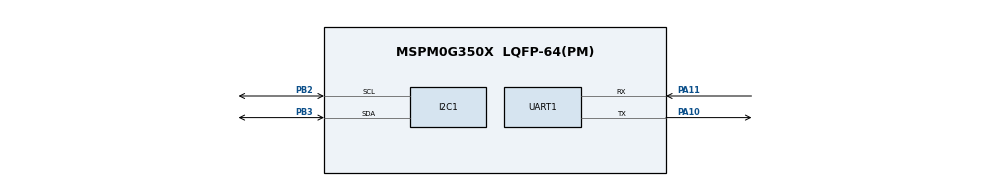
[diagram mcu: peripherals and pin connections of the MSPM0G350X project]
/**
 * @cliArgs --device "MSPM0G350X" --package "LQFP-64(PM)" --part "Default" --product "mspm0_sdk@2.01.00.03"
 * @versions {"tool":"1.20.0+3587"}
 */

/**
 * Import the modules used in this configuration.
 */
const I2C    = scripting.addModule("/ti/driverlib/I2C", {}, false);
const I2C1   = I2C.addInstance();
const SYSCTL = scripting.addModule("/ti/driverlib/SYSCTL");
const UART   = scripting.addModule("/ti/driverlib/UART", {}, false);
const UART1  = UART.addInstance();

/**
 * Write custom configuration values to the imported modules.
 */
I2C1.basicEnableController             = true;
I2C1.$name                             = "I2C_MPU6050";
I2C1.advControllerTXFIFOTRIG           = "BYTES_1";
I2C1.intController                     = ["ARBITRATION_LOST","NACK","RXFIFO_TRIGGER","RX_DONE","TX_DONE"];
I2C1.peripheral.$assign                = "I2C1";
I2C1.peripheral.sdaPin.$assign         = "PB3";
I2C1.peripheral.sclPin.$assign         = "PB2";
I2C1.sdaPinConfig.hideOutputInversion  = scripting.forceWrite(false);
I2C1.sdaPinConfig.onlyInternalResistor = scripting.forceWrite(false);
I2C1.sdaPinConfig.passedPeripheralType = scripting.forceWrite("Digital");
I2C1.sdaPinConfig.$name                = "ti_driverlib_gpio_GPIOPinGeneric2";
I2C1.sclPinConfig.hideOutputInversion  = scripting.forceWrite(false);
I2C1.sclPinConfig.onlyInternalResistor = scripting.forceWrite(false);
I2C1.sclPinConfig.passedPeripheralType = scripting.forceWrite("Digital");
I2C1.sclPinConfig.$name                = "ti_driverlib_gpio_GPIOPinGeneric3";

const Board = scripting.addModule("/ti/driverlib/Board", {}, false);

SYSCTL.forceDefaultClkConfig = true;

UART1.$name                    = "UART_0";
UART1.peripheral.rxPin.$assign = "PA11";
UART1.peripheral.txPin.$assign = "PA10";
UART1.txPinConfig.$name        = "ti_driverlib_gpio_GPIOPinGeneric0";
UART1.rxPinConfig.$name        = "ti_driverlib_gpio_GPIOPinGeneric1";

/**
 * Pinmux solution for unlocked pins/peripherals. This ensures that minor changes to the automatic solver in a future
 * version of the tool will not impact the pinmux you originally saw.  These lines can be completely deleted in order to
 * re-solve from scratch.
 */
Board.peripheral.$suggestSolution          = "DEBUGSS";
Board.peripheral.swclkPin.$suggestSolution = "PA20";
Board.peripheral.swdioPin.$suggestSolution = "PA19";
SYSCTL.peripheral.$suggestSolution         = "SYSCTL";
UART1.peripheral.$suggestSolution          = "UART0";
